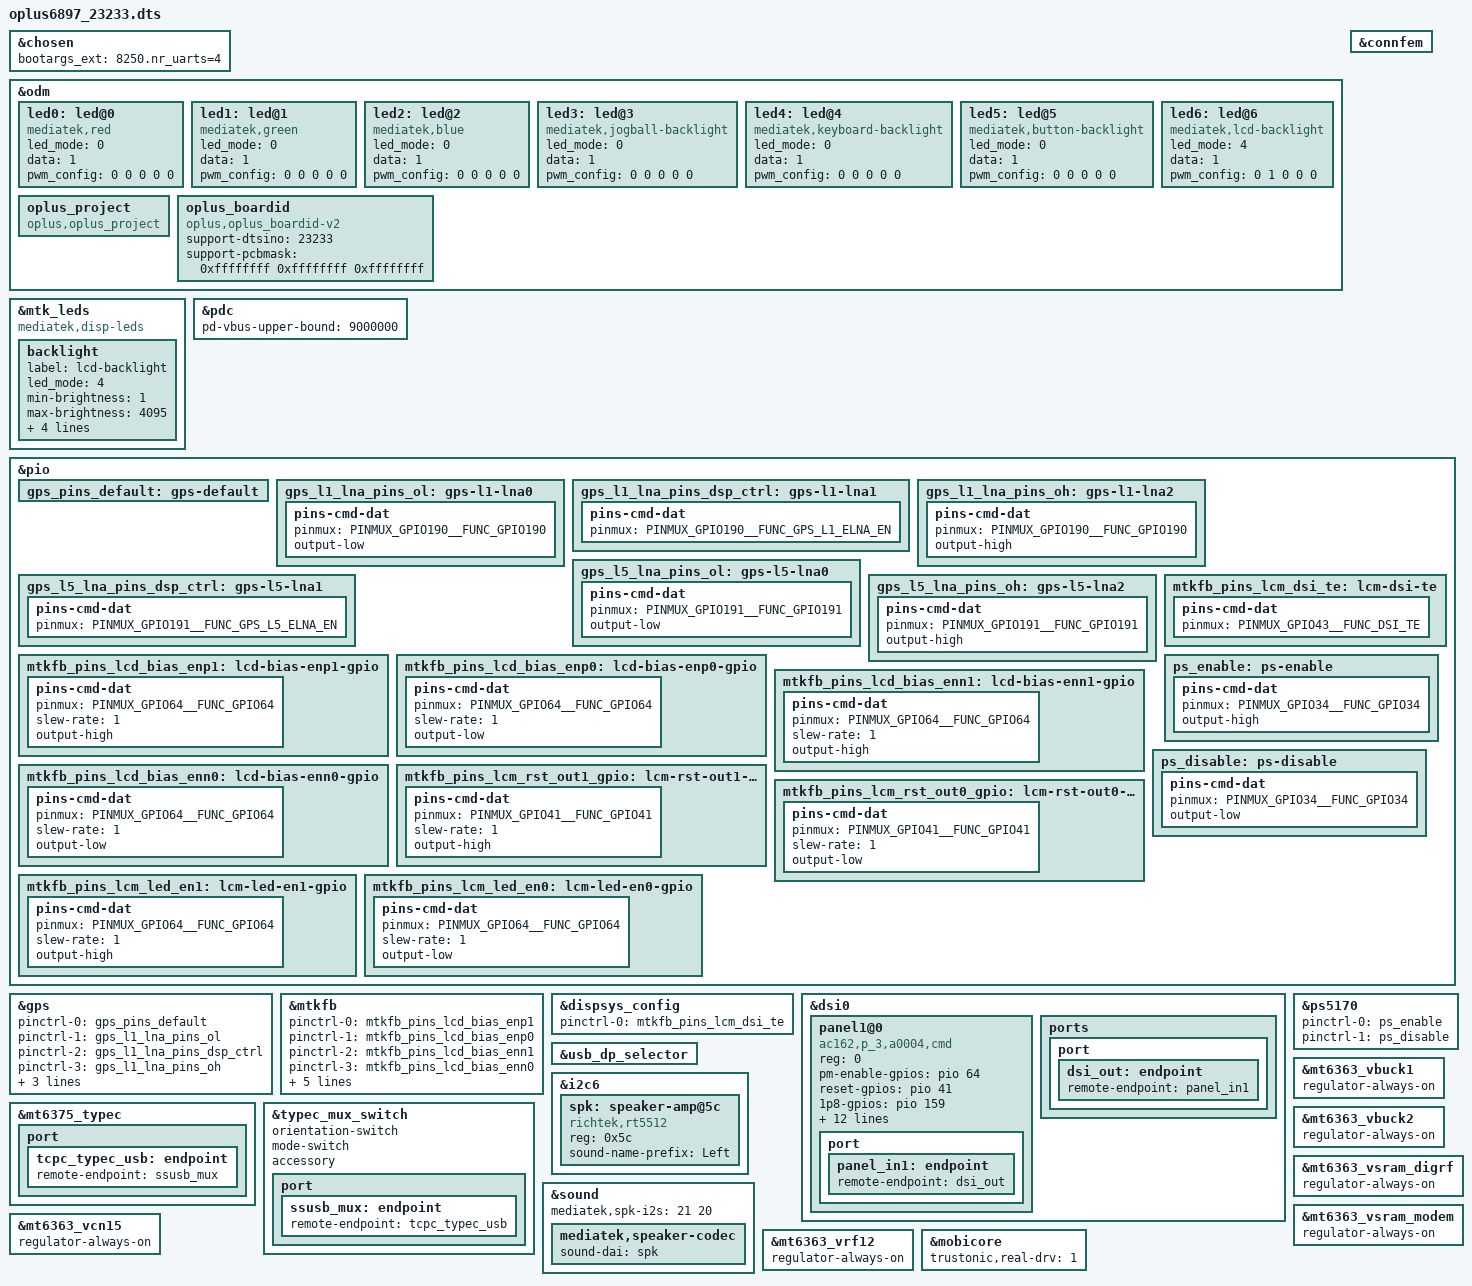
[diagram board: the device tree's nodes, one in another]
// SPDX-License-Identifier: (GPL-2.0 OR MIT)
/*
 * Copyright (C) 2022 MediaTek Inc.
 */
/dts-v1/;
/plugin/;
#include <dt-bindings/interrupt-controller/arm-gic.h>
#include <dt-bindings/interrupt-controller/irq.h>
#include <dt-bindings/pinctrl/mt6897-pinfunc.h>
#include <dt-bindings/phy/phy.h>

&chosen {
bootargs_ext = "8250.nr_uarts=4";
};

/* #ifdef OPLUS_DISPLAY_FEATURE */
&odm {
	led0:led@0 {
		compatible = "mediatek,red";
		led_mode = <0>;
		data = <1>;
		pwm_config = <0 0 0 0 0>;
	};
	led1:led@1 {
		compatible = "mediatek,green";
		led_mode = <0>;
		data = <1>;
		pwm_config = <0 0 0 0 0>;
	};
	led2:led@2 {
		compatible = "mediatek,blue";
		led_mode = <0>;
		data = <1>;
		pwm_config = <0 0 0 0 0>;
	};
	led3:led@3 {
		compatible = "mediatek,jogball-backlight";
		led_mode = <0>;
		data = <1>;
		pwm_config = <0 0 0 0 0>;
	};
	led4:led@4 {
		compatible = "mediatek,keyboard-backlight";
		led_mode = <0>;
		data = <1>;
		pwm_config = <0 0 0 0 0>;
	};
	led5:led@5 {
		compatible = "mediatek,button-backlight";
		led_mode = <0>;
		data = <1>;
		pwm_config = <0 0 0 0 0>;
	};
	led6:led@6 {
		compatible = "mediatek,lcd-backlight";
		led_mode = <4>;
		data = <1>;
		pwm_config = <0 1 0 0 0>;
	};
};

/*  OPLUS_DISPLAY_FEATURE */
&mtk_leds {
	compatible = "mediatek,disp-leds";
	status = "okay";

	backlight {
		label = "lcd-backlight";
		led_mode = <4>;
		min-brightness = <1>;
		max-brightness = <4095>;
		max-hw-brightness = <4095>;
		led-bits = <13>;
		trans-bits = <13>;
		default-state = "on";
	};
};
/*  OPLUS_DISPLAY_FEATURE */

&pdc {
	pd-vbus-upper-bound = <9000000>;
};

&connfem {
/* Enable epa_elna node to support Wifi & BT ePA/eLNA FEM on customer load */
#if 0
	epa-elna {
		parts = <&wlan7207h &wlan7207c>;
		wifi {
			flags-0 {
				open-loop;
			};
		};
		bt {
			flags-0 {
				/* choose one of: epa-elna/epa/elna/bypass */
				epa-elna;
			};
		};
	};
#endif
};

/* GPS GPIO standardization start */
&pio {
	gps_pins_default: gps-default {
	};
	gps_l1_lna_pins_ol: gps-l1-lna0 {
		pins-cmd-dat {
			pinmux = <PINMUX_GPIO190__FUNC_GPIO190>;
			output-low;
		};
	};
	gps_l1_lna_pins_dsp_ctrl: gps-l1-lna1 {
		pins-cmd-dat {
			pinmux = <PINMUX_GPIO190__FUNC_GPS_L1_ELNA_EN>;
		};
	};
	gps_l1_lna_pins_oh: gps-l1-lna2 {
		pins-cmd-dat {
			pinmux = <PINMUX_GPIO190__FUNC_GPIO190>;
			output-high;
		};
	};
	gps_l5_lna_pins_ol: gps-l5-lna0 {
		pins-cmd-dat {
			pinmux = <PINMUX_GPIO191__FUNC_GPIO191>;
			output-low;
		};
	};
	gps_l5_lna_pins_dsp_ctrl: gps-l5-lna1 {
		pins-cmd-dat {
			pinmux = <PINMUX_GPIO191__FUNC_GPS_L5_ELNA_EN>;
		};
	};
	gps_l5_lna_pins_oh: gps-l5-lna2 {
		pins-cmd-dat {
			pinmux = <PINMUX_GPIO191__FUNC_GPIO191>;
			output-high;
		};
	};
};
&gps {
	pinctrl-names = "default",
		"gps_l1_lna_disable",
		"gps_l1_lna_dsp_ctrl",
		"gps_l1_lna_enable",
		"gps_l5_lna_disable",
		"gps_l5_lna_dsp_ctrl",
		"gps_l5_lna_enable";
	pinctrl-0 = <&gps_pins_default>;
	pinctrl-1 = <&gps_l1_lna_pins_ol>;
	pinctrl-2 = <&gps_l1_lna_pins_dsp_ctrl>;
	pinctrl-3 = <&gps_l1_lna_pins_oh>;
	pinctrl-4 = <&gps_l5_lna_pins_ol>;
	pinctrl-5 = <&gps_l5_lna_pins_dsp_ctrl>;
	pinctrl-6 = <&gps_l5_lna_pins_oh>;
	status = "okay";
};
/* GPS GPIO standardization end */

&pio {
	mtkfb_pins_lcd_bias_enp1: lcd-bias-enp1-gpio {
		pins-cmd-dat {
			pinmux = <PINMUX_GPIO64__FUNC_GPIO64>;
			slew-rate = <1>;
			output-high;
		};
	};

	mtkfb_pins_lcd_bias_enp0: lcd-bias-enp0-gpio {
		pins-cmd-dat {
			pinmux = <PINMUX_GPIO64__FUNC_GPIO64>;
			slew-rate = <1>;
			output-low;
		};
	};

	mtkfb_pins_lcd_bias_enn1: lcd-bias-enn1-gpio {
		pins-cmd-dat {
			pinmux = <PINMUX_GPIO64__FUNC_GPIO64>;
			slew-rate = <1>;
			output-high;
		};
	};

	mtkfb_pins_lcd_bias_enn0: lcd-bias-enn0-gpio {
		pins-cmd-dat {
			pinmux = <PINMUX_GPIO64__FUNC_GPIO64>;
			slew-rate = <1>;
			output-low;
		};
	};

	mtkfb_pins_lcm_rst_out1_gpio: lcm-rst-out1-gpio {
		pins-cmd-dat {
			pinmux = <PINMUX_GPIO41__FUNC_GPIO41>;
			slew-rate = <1>;
			output-high;
		};
	};

	mtkfb_pins_lcm_rst_out0_gpio: lcm-rst-out0-gpio {
		pins-cmd-dat {
			pinmux = <PINMUX_GPIO41__FUNC_GPIO41>;
			slew-rate = <1>;
			output-low;
		};
	};
	mtkfb_pins_lcm_dsi_te: lcm-dsi-te {
		pins-cmd-dat {
			pinmux = <PINMUX_GPIO43__FUNC_DSI_TE>;
		};
	};

	mtkfb_pins_lcm_led_en1: lcm-led-en1-gpio {
		pins-cmd-dat {
			pinmux = <PINMUX_GPIO64__FUNC_GPIO64>;
			slew-rate = <1>;
			output-high;
		};
	};

	mtkfb_pins_lcm_led_en0: lcm-led-en0-gpio {
		pins-cmd-dat {
			pinmux = <PINMUX_GPIO64__FUNC_GPIO64>;
			slew-rate = <1>;
			output-low;
		};
	};
};

&mtkfb {
	pinctrl-names = "lcd_bias_enp1_gpio", "lcd_bias_enp0_gpio",
		"lcd_bias_enn1_gpio", "lcd_bias_enn0_gpio",
		"lcm_rst_out1_gpio", "lcm_rst_out0_gpio",
		"mode_te_te", "lcm_led_en1_gpio", "lcm_led_en0_gpio";
	pinctrl-0 = <&mtkfb_pins_lcd_bias_enp1>;
	pinctrl-1 = <&mtkfb_pins_lcd_bias_enp0>;
	pinctrl-2 = <&mtkfb_pins_lcd_bias_enn1>;
	pinctrl-3 = <&mtkfb_pins_lcd_bias_enn0>;
	pinctrl-4 = <&mtkfb_pins_lcm_rst_out1_gpio>;
	pinctrl-5 = <&mtkfb_pins_lcm_rst_out0_gpio>;
	pinctrl-6 = <&mtkfb_pins_lcm_dsi_te>;
	pinctrl-7 = <&mtkfb_pins_lcm_led_en1>;
	pinctrl-8 = <&mtkfb_pins_lcm_led_en0>;

	status = "okay";
};

&dispsys_config {
	pinctrl-names = "mode_te_te";
	pinctrl-0 = <&mtkfb_pins_lcm_dsi_te>;
	status = "okay";
};

&dsi0 {
	status = "okay";
	#address-cells = <1>;
	#size-cells = <0>;
	/** #ifdef OPLUS_DISPLAY_FEATURE **/
	panel1@0 {
		compatible = "ac162,p_3,a0004,cmd";
		reg = <0>;
		pm-enable-gpios = <&pio 64 0>;
		reset-gpios = <&pio 41 0>;
		1p8-gpios = <&pio 159 0>;
		3p0-supply = <&mt6368_vmc>;
		oplus,dsi-serial-number-enabled=<1>;
		oplus,dsi-serial-number-switch-page;
		oplus,dsi-serial-number-index= <0>;
		oplus,dsi-serial-number-switch-page-command= <0xFF 0x08 0x38 0x1D>;
		oplus,dsi-read-reg-da-switch-page-command= <0xFF 0x08 0x38 0x00>;
		oplus,dsi-serial-number-default-switch-page-command= <0xFF 0x08 0x38 0x20>;
		oplus,dsi-serial-number-reg= <0x81>;
		oplus,dsi-serial-number-read-count= <7>;
		pinctrl-names = "default";
		port {
			panel_in1: endpoint {
				remote-endpoint = <&dsi_out>;
			};
		};
	};
	ports {
		port {
			dsi_out: endpoint {
				remote-endpoint = <&panel_in1>;
			};
		};
	};
};

/* usb typec mux start */
&pio {

	ps_enable: ps-enable {
		pins-cmd-dat {
			pinmux = <PINMUX_GPIO34__FUNC_GPIO34>;
			output-high;
		};
	};

	ps_disable: ps-disable {
		pins-cmd-dat {
			pinmux = <PINMUX_GPIO34__FUNC_GPIO34>;
			output-low;
		};
	};

};

&mt6375_typec {
	port {
		tcpc_typec_usb: endpoint {
			remote-endpoint = <&ssusb_mux>;
		};
	};
};

&typec_mux_switch {
	orientation-switch;
	mode-switch;
	accessory;
	port {
		ssusb_mux: endpoint {
			remote-endpoint = <&tcpc_typec_usb>;
		};
	};
};

&ps5170 {
	pinctrl-names = "enable", "disable";
	pinctrl-0 = <&ps_enable>;
	pinctrl-1 = <&ps_disable>;
	status = "okay";
};

&usb_dp_selector {
	status = "okay";
};
/* usb typec mux end */

&i2c6 {
	spk: speaker-amp@5c {
		compatible = "richtek,rt5512";
		#address-cells = <1>;
		#size-cells = <0>;
		#sound-dai-cells = <0>;
		reg = <0x5c>;
		status = "okay";
		sound-name-prefix = "Left";
	};
};

&odm {
/*OPLUS_FEATURE_OEM_OCDT oppo project start */
	oplus_project:oplus_project {
		compatible = "oplus,oplus_project";
	};

	oplus_boardid:oplus_boardid {
		compatible = "oplus,oplus_boardid-v2";
		support-dtsino=<23233>;//only one u32
		/*first one is low 32bit, last one is highest 32bit, must be 32-bit for 4gpios*/
		support-pcbmask=<0xffffffff 0xffffffff 0xffffffff>;
	};
};

&sound {
	mediatek,spk-i2s = <21 20>;
	mediatek,speaker-codec {
		sound-dai = <&spk>;
	};
};

&mt6363_vbuck1 {
	regulator-always-on;
};

&mt6363_vbuck2 {
	regulator-always-on;
};

&mt6363_vsram_digrf {
	regulator-always-on;
};

&mt6363_vsram_modem {
	regulator-always-on;
};

&mt6363_vcn15 {
	regulator-always-on;
};

&mt6363_vrf12 {
	regulator-always-on;
};

/*
 * Trustonic Mobilecore real driver
 */
&mobicore{
        trustonic,real-drv = <1>;
};

#include "mediatek/cust_k6897_connfem.dtsi"
#include "mediatek/cust_mt6897_touch_1080x2400.dtsi"
#include "mediatek/cust_mt6897_camera_v4l2.dtsi"
#include <oplus6897_23233/cust.dtsi>
/*End of this file, DO NOT ADD ANYTHING HERE*/
